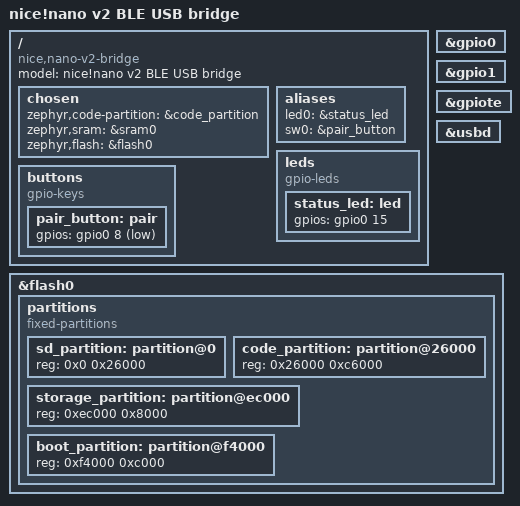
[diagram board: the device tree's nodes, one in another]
/dts-v1/;
#include <nordic/nrf52840_qiaa.dtsi>
#include <zephyr/dt-bindings/gpio/gpio.h>

/ {
    model = "nice!nano v2 BLE USB bridge";
    compatible = "nice,nano-v2-bridge";
    chosen {
        zephyr,code-partition = &code_partition;
        zephyr,sram = &sram0;
        zephyr,flash = &flash0;
    };
    aliases { led0 = &status_led; sw0 = &pair_button; };
    leds {
        compatible = "gpio-leds";
        status_led: led { gpios = <&gpio0 15 GPIO_ACTIVE_HIGH>; };
    };
    buttons {
        compatible = "gpio-keys";
        /* Optional button: nice!nano D0/P0.08 to GND; never use RESET. */
        pair_button: pair { gpios = <&gpio0 8 (GPIO_PULL_UP | GPIO_ACTIVE_LOW)>; };
    };
};
&gpio0 { status = "okay"; };
&gpio1 { status = "okay"; };
&gpiote { status = "okay"; };
&usbd { status = "okay"; };
&flash0 {
    partitions {
        compatible = "fixed-partitions";
        #address-cells = <1>;
        #size-cells = <1>;
        sd_partition: partition@0 { reg = <0x0 0x26000>; };
        code_partition: partition@26000 { reg = <0x26000 0xc6000>; };
        storage_partition: partition@ec000 { reg = <0xec000 0x8000>; };
        boot_partition: partition@f4000 { reg = <0xf4000 0xc000>; };
    };
};
